# TPCC register map
Vendor: Texas Instruments
Peripheral module from a debugger description file (folder omap4430).
Registers are 32-bit, read-write, reset values left out (the file's numbers can be read two ways) unless marked. A register's access mark holds for its fields unless they carry their own. Offsets are as the file gives them; lines under a group give offsets from that group; [hi:lo] are bit positions; {n}, {i} and the like mark numbered series; 'fields as' and 'values as' point back to an identical list; <NAME> marks a mode.

## TPCC (part 1 of 2)
0x00 TPCC_PID ro — Peripheral ID Register
  [31:0] REVISION — IP Revision
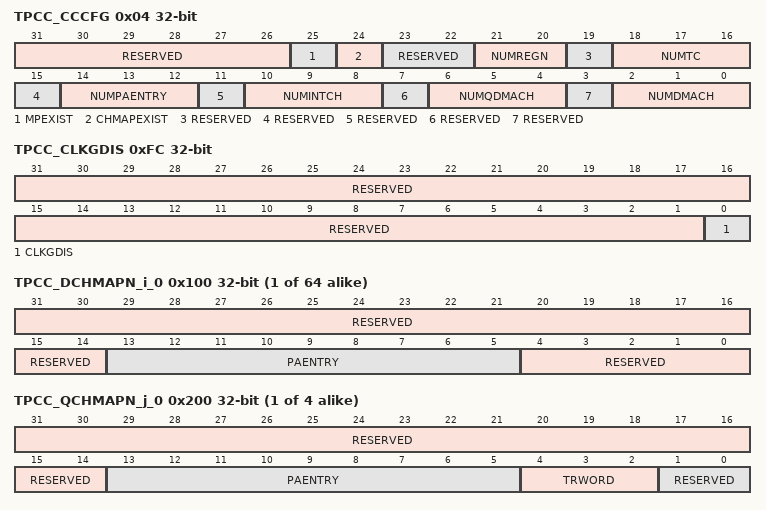
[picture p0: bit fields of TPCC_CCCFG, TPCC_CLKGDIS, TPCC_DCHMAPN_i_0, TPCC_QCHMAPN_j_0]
0x04 TPCC_CCCFG ro — CC Configuration Register
  [31:26] RESERVED — reads return 0's
  [25] MPEXIST — Memory Protection Existence0 : No memory protection.1 : Memory Protection logic included.
  [24] CHMAPEXIST — Channel Mapping Existence0 : No Channel mapping.1 : Channel mapping logic included.
  [23:22] RESERVED — reads return 0's
  [21:20] NUMREGN — Number of MP and Shadow regions
    0=NUMREGN_0_r (0 Regions); 1=NUMREGN_1_r (2 Regions); 2=NUMREGN_2_r (4 Regions); 3=NUMREGN_3_r (8 Regions)
  [19] RESERVED — reads return 0's
  [18:16] NUMTC — Number of Queues/Number of TCs
    {v}=NUMTC_{v}_r ({v+1} TC/Event Queue) (v=0..7)
  [15] RESERVED — reads return 0's
  [14:12] NUMPAENTRY — Number of PaRAM entries
    0=NUMPAENTRY_0_r (16 entries); 1=NUMPAENTRY_1_r (32 entries (unsupported setting)); 2=NUMPAENTRY_2_r (64 entries); 3=NUMPAENTRY_3_r (128 entries); 4=NUMPAENTRY_4_r (256 entries); 5=NUMPAENTRY_5_r (512 entries)
  [11] RESERVED — reads return 0's
  [10:8] NUMINTCH — Number of Interrupt Channels
    1=NUMINTCH_1_r (8 Interrupt channels); 2=NUMINTCH_2_r (16 Interrupt channels); 3=NUMINTCH_3_r (32 Interrupt channels); 4=NUMINTCH_4_r (64 Interrupt channels)
  [7] RESERVED — reads return 0's
  [6:4] NUMQDMACH — Number of QDMA Channels
    0=NUMQDMACH_0_r (No QDMA Channels); 1=NUMQDMACH_1_r (2 QDMA Channels); 2=NUMQDMACH_2_r (4 QDMA Channels); 3=NUMQDMACH_3_r (6 QDMA Channels); 4=NUMQDMACH_4_r (8 QDMA Channels)
  [3] RESERVED — reads return 0's
  [2:0] NUMDMACH — Number of DMA Channels
    0=NUMDMACH_0_r (No DMA Channels); 1=NUMDMACH_1_r (4 DMA Channels); 2=NUMDMACH_2_r (8 DMA Channels); 3=NUMDMACH_3_r (16 DMA Channels); 4=NUMDMACH_4_r (32 DMA Channels); 5=NUMDMACH_5_r (64 DMA Channels)
0xFC TPCC_CLKGDIS — Auto Clock Gate Disable
  [31:1] RESERVED — write 0's for future compatibility reads return 0's
  [0] CLKGDIS — Auto Clock Gate Disable
{0x100+4i} TPCC_DCHMAPN_i_{i} (i=0..63) — DMA Channel N Mapping Register
  [31:14] RESERVED — write 0's for future compatibility reads return 0's
  [13:5] PAENTRY — PaRAM Entry number for DMA Channel N.
  [4:0] RESERVED — write 0's for future compatibility reads return 0's
{0x200+4i} TPCC_QCHMAPN_j_{i} (i=0..3) — QDMA Channel N Mapping Register
  [31:14] RESERVED — write 0's for future compatibility reads return 0's
  [13:5] PAENTRY — PaRAM Entry number for QDMA Channel N.
  [4:2] TRWORD — TRWORD points to the specific trigger word of the PaRAM Entry defined by PAENTRY. A write to the trigger word results in a QDMA Event being recognized.
  [1:0] RESERVED — write 0's for future compatibility reads return 0's
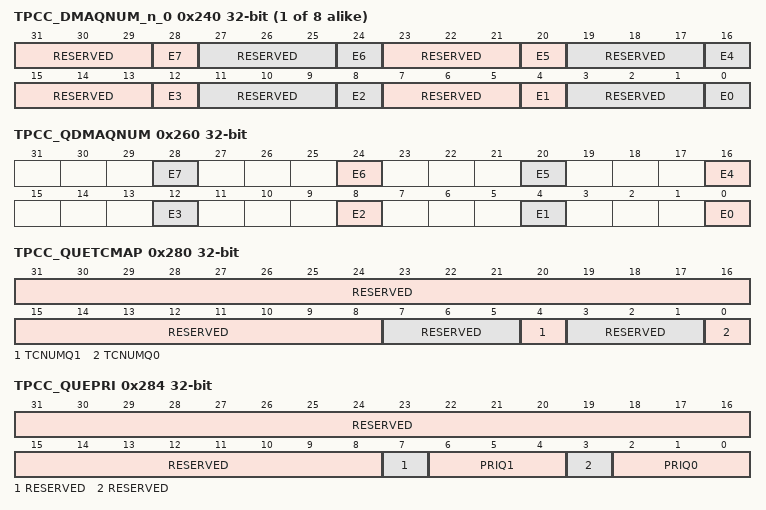
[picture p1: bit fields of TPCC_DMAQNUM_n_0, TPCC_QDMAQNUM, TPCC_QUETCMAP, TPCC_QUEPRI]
{0x240+4i} TPCC_DMAQNUM_n_{i} (i=0..7) — DMA Queue Number Register ncontains the Event queue number to be used for the corresponding DMA Channel.
  [31:29] RESERVED — Write 0s for future compatibility. Reads return 0s.
  [4n] E{n} (n=0..7) — DMA Queue Number for event #(8 * n + {n})
    0=Event En is queued on Q0; 1=Event En is queued on Q1
  [27:25] RESERVED — Write 0s for future compatibility. Reads return 0s.
  [23:21] RESERVED — Write 0s for future compatibility. Reads return 0s.
  [19:17] RESERVED — Write 0s for future compatibility. Reads return 0s.
  [15:13] RESERVED — Write 0s for future compatibility. Reads return 0s.
  [11:9] RESERVED — Write 0s for future compatibility. Reads return 0s.
  [7:5] RESERVED — Write 0s for future compatibility. Reads return 0s.
  [3:1] RESERVED — Write 0s for future compatibility. Reads return 0s.
0x260 TPCC_QDMAQNUM access per field — QDMA Queue Number RegisterContains the Event queue number to be used for the corresponding QDMA Channel.
  [all] fields
    0=Event En is queued on Q0; 1=Event En is queued on Q1
  [4n] E{n} rw (n=0..7) — QDMA Queue Number for event #{n}
0x280 TPCC_QUETCMAP — Queue to TC Mapping
  [31:8] RESERVED — Write 0s for future compatibility. Reads return 0s.
  [7:5] RESERVED — Write 0s for future compatibility. Reads return 0s.
  [4] TCNUMQ1 — TC Number for Queue N: Defines the TC number that Event Queue N TRs are written to.
    0=TRs from this queue are routed to TC0; 1=TRs from this queue are routed to TC1
  [3:1] RESERVED — Write 0s for future compatibility. Reads return 0s.
  [0] TCNUMQ0 — TC Number for Queue N: Defines the TC number that Event Queue N TRs are written to.
    values as TCNUMQ1
0x284 TPCC_QUEPRI — Queue Priority
  [31:8] RESERVED — write 0's for future compatibility reads return 0's
  [7] RESERVED — write 0's for future compatibility reads return 0's
  [6:4] PRIQ1 — Priority Level for Queue 1 Dictates the priority level used for the OPTIONS field programmation for Qn TRs. Sets the priority used for TC read and write commands.
    0=Priority 0 - Highest priority; {v}=Priority {v} (v=1..6); 7=Priority 7 - Lowest Priority
  [3] RESERVED — write 0's for future compatibility reads return 0's
  [2:0] PRIQ0 — Priority Level for Queue 0 Dictates the priority level used for the OPTIONS field programmation for Qn TRs. Sets the priority used for TC read and write commands.
    values as PRIQ1
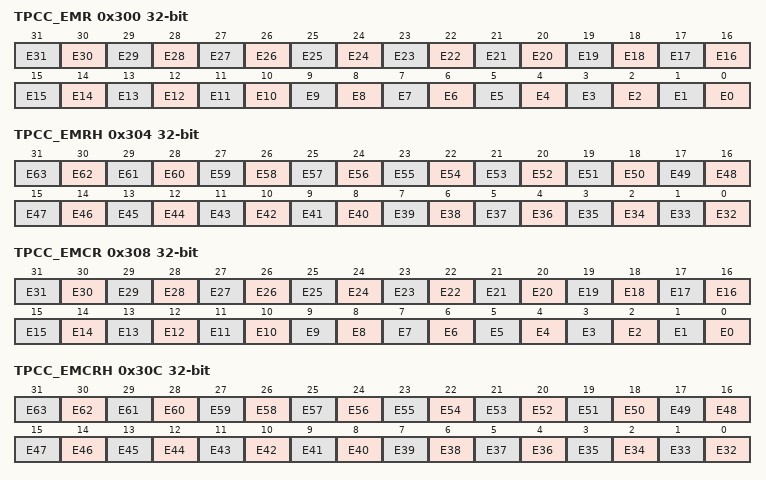
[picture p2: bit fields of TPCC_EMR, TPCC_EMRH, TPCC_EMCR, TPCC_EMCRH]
0x300 TPCC_EMR ro — Event Missed Register:The Event Missed register is set if 2 events are received without the first event being cleared or if a Null TR is serviced.Chained events (CER), Set Events (ESR), and normal events (ER) are treated individually. If any bit in the EMR register is set (and all errors (including QEMR/CCERR) were previously clear), then an error will be signaled with TPCC error interrupt.
  [n] E{n} (n=0..31) — Event Missed #{n}
0x304 TPCC_EMRH ro — Event Missed Register (High Part):The Event Missed register is set if 2 events are received without the first event being cleared or if a Null TR is serviced.Chained events (CER), Set Events (ESR), and normal events (ER) are treated individually. If any bit in the EMR register is set (and all errors (including QEMR/CCERR) were previously clear), then an error will be signaled with TPCC error interrupt.
  [n-32] E{n} (n=32..63) — Event Missed #{n}
0x308 TPCC_EMCR wo — Event Missed Clear Register:CPU write of 1 to the [n] En bit causes the [n] En bit to be cleared.CPU write of 0 has no effect.. All error bits must be cleared before additional error interrupts will be asserted by CC.
  [n] E{n} (n=0..31) — Event Missed Clear #{n}
0x30C TPCC_EMCRH wo — Event Missed Clear Register (High Part):CPU write of 1 to the [n] En bit causes the [n] En bit to be cleared.CPU write of 0 has no effect.. All error bits must be cleared before additional error interrupts will be asserted by CC.
  [n-32] E{n} (n=32..63) — Event Missed Clear #{n}
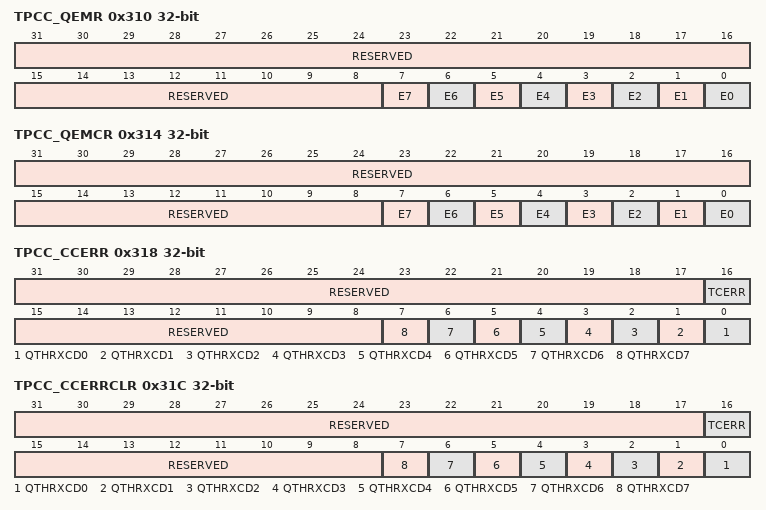
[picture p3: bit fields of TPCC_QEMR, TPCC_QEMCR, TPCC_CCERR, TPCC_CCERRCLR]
0x310 TPCC_QEMR ro — QDMA Event Missed Register:The QDMA Event Missed register is set if 2 QDMA events are detected without the first event being cleared or if a Null TR is serviced. If any bit in the register is set (and all errors (including /) were previously clear), then an error will be signaled with TPCC error interrupt.
  [31:8] RESERVED — reads return 0's
  [n] E{n} (n=0..7) — Event Missed #{n}
0x314 TPCC_QEMCR wo — QDMA Event Missed Clear Register:CPU write of 1 to the [n] En bit causes the [n] En bit to be cleared. CPU write of 0 has no effect.All error bits must be cleared before additional error interrupts will be asserted by CC.
  [31:8] RESERVED — write 0's for future compatibility
  [n] E{n} (n=0..7) — Event Missed Clear #{n}
0x318 TPCC_CCERR ro — CC Error RegisterEach bit can be cleared by writing a 1 to corresponding bit in register.If any bit in the register is set (and all errors were previously clear), then an error will be signaled with TPCC error interrupt.
  [31:17] RESERVED — reads return 0's
  [16] TCERR — Transfer Completion Code Error:0 : Total number of allowed TCCs outstanding has not been reached.1 : Total number of allowed TCCs has been reached.
  [15:8] RESERVED — reads return 0's
  [n] QTHRXCD{n} (n=0..7) — Queue Threshold Error for Q{n}:0 : Watermark/threshold has not been exceeded.1 : Watermark/threshold has been exceeded.
0x31C TPCC_CCERRCLR wo — CC Error Clear Register
  [31:17] RESERVED — write 0's for future compatibility
  [16] TCERR — Clear Error for TCERR:Write of 1 clears the value of TPCC_CCERR bit N.Writes of 0 have no affect.
  [15:8] RESERVED — write 0's for future compatibility
  [n] QTHRXCD{n} (n=0..7) — Clear error for QTHRXCD{n}:Write of 1 clears the values of QSTATN_{n}[20:16] WM, QSTATN_{n}[24] THRXCD, QTHRXCD{n}Writes of 0 have no affect.
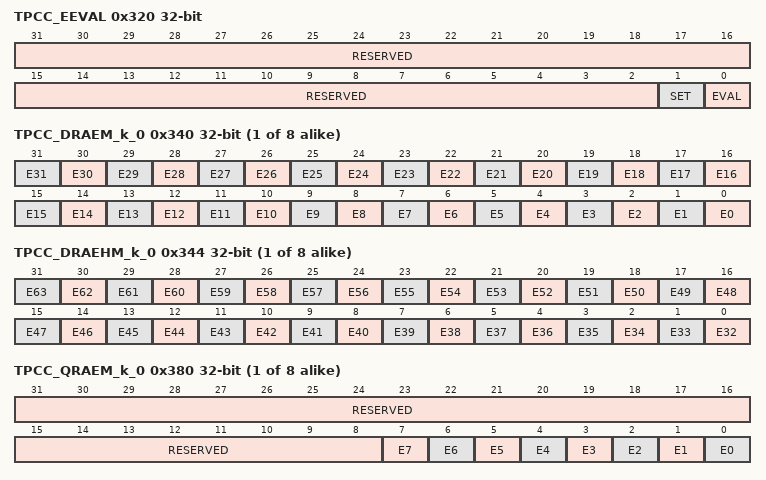
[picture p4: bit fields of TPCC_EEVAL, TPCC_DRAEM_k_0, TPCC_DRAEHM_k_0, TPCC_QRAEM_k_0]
0x320 TPCC_EEVAL wo — Error Eval Register
  [31:2] RESERVED — write 0's for future compatibility
  [1] SET — Error Interrupt Set:CPU write of 1 to the SET bit causes the TPCC error interrupt to be pulsed regardless of state of TPCC_EMR/TPCC_EMRH, TPCC_QEMR, or CPUwrite of 0 has no effect.
  [0] EVAL — Error Interrupt Evaluate:CPU write of 1 to the EVAL bit causes the TPCC error interrupt to be pulsed if any errors have not been cleared in the TPCC_EMR/TPCC_EMRH, TPCC_QEMR, or TPCC_CCERR registers.CPU write of 0 has no effect.
{0x340+8i} TPCC_DRAEM_k_{i} (i=0..7) — DMA Region Access enable for bit N in Region M:En = 0 : Accesses via Region M address space to Bit N in any DMA Channel Register are not allowed. Reads will return 0 on Bit N and writes will not modify the state of bit N. Enabled interrupt bits for bit N do not contribute to the generation of the TPCC region M interrupt.En = 1 : Accesses via Region M address space to Bit N in any DMA Channel Register are allowed. Reads will return the value from Bit N and writes will modify the state of bit N. Enabled interrupt bits for bit N do contribute to the generation of the TPCC region M interrupt.
  [n] E{n} (n=0..31) — DMA Region Access enable for Region M, bit #{n}
{0x344+8i} TPCC_DRAEHM_k_{i} (i=0..7) — DMA Region Access enable for bit N in Region M:En = 0 : Accesses via Region M address space to Bit N in any DMA Channel Register are not allowed. Reads will return 'b0 on Bit N and writes will not modify the state of bit N. Enabled interrupt bits for bit N do not contribute to the generation of the TPCC region M interrupt.En = 1 : Accesses via Region M address space to Bit N in any DMA Channel Register are allowed. Reads will return the value from Bit N and writes will modify the state of bit N. Enabled interrupt bits for bit N do contribute to the generation of the TPCC region M interrupt. En = 0 : Accesses via Region M address space to Bit N in any DMA Channel Register are not allowed. Reads will return 'b0 on Bit N and writes will not modify the state of bit N. Enabled interrupt bits for bit N do not contribute to the generation of the TPCC region M interrupt. En = 1 : Accesses via Region M address space to Bit N in any DMA Channel Register are allowed. Reads will return the value from Bit N and writes will modify the state of bit N. Enabled interrupt bits for bit N do contribute to the generation of the TPCC region M interrupt.
  [n-32] E{n} (n=32..63) — DMA Region Access enable for Region M, bit #{n}
{0x380+4i} TPCC_QRAEM_k_{i} (i=0..7) — QDMA Region Access enable for bit N in Region M:En = 0 : Accesses via Region M address space to Bit N in any QDMA Channel Register are not allowed. Reads will return 'b0 on Bit N and writes will not modify the state of bit N. Enabled interrupt bits for bit N do not contribute to the generation of the TPCC region M interrupt.En = 1 : Accesses via Region M address space to Bit N in any QDMA Channel Register are allowed. Reads will return the value from Bit N and writes will modify the state of bit N. Enabled interrupt bits for bit N do contribute to the generation of the TPCC region M interrupt.
  [31:8] RESERVED — write 0's for future compatibility reads return 0's
  [n] E{n} (n=0..7) — QDMA Region Access enable for Region M, bit #{n}
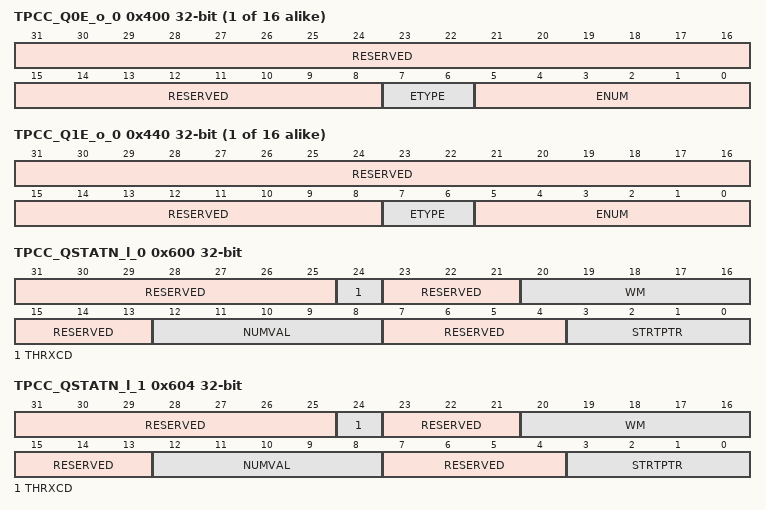
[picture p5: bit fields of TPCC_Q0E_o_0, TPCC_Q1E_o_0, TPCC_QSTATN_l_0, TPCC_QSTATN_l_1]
{0x400+4i} TPCC_Q0E_o_{i} ro (i=0..15) — Event Queue Entry Diagram for Queue 0 - Entry o
  [31:8] RESERVED — reads return 0's
  [7:6] ETYPE — Event Type:Specifies the specific Event Type for the given entry in the Event Queue.
    0=ETYPE_0_r (Event Triggered via ER); 1=ETYPE_1_r (Manual Triggered via ESR); 2=ETYPE_2_r (Chain Triggered via CER); 3=ETYPE_3_r (Auto-Triggered via QER)
  [5:0] ENUM — Event Number:Specifies the specific Event Number for the given entry in the Event Queue. For DMA Channel events (ER/ESR/CER), ENUM will range between 0 and NUM_DMACH (up to 63). For QDMA Channel events (QER), ENUM will range between 0 and NUM_QDMACH (up to 7).
{0x440+4i} TPCC_Q1E_o_{i} ro (i=0..15) — Event Queue Entry Diagram for Queue 1 - Entry o
  fields as TPCC_Q0E_o_0
0x600 TPCC_QSTATN_l_0 ro — QSTATn Register Set
  [31:25] RESERVED — reads return 0's
  [24] THRXCD — Threshold Exceeded:0 : Threshold specified by QWMTHR(A|B).Qn has not been exceeded.1 : Threshold specified by QWMTHR(A|B).Qn has been exceeded.THRXCD is cleared via WMCLRn bit.
  [23:21] RESERVED — reads return 0's
  [20:16] WM — Watermark for Maximum Queue Usage:Watermark tracks the most entries that have been in QueueN since reset or since the last time that the watermark (WM) was cleared.WM is cleared via WMCLRn bit.Legal values = 0x0 (empty) to 0x10 (full)
  [15:13] RESERVED — reads return 0's
  [12:8] NUMVAL — Number of Valid Entries in QueueN:Represents the total number of entries residing in the Queue Manager FIFO at a given instant. Always enabled.Legal values = 0x0 (empty) to 0x10 (full)
  [7:4] RESERVED — reads return 0's
  [3:0] STRTPTR — Start Pointer:Represents the offset to the head entry of QueueN, in units of *entries*. Always enabled.Legal values = 0x0 (0th entry) to 0xF (15th entry)
0x604 TPCC_QSTATN_l_1 ro — QSTATn Register Set
  fields as TPCC_QSTATN_l_0
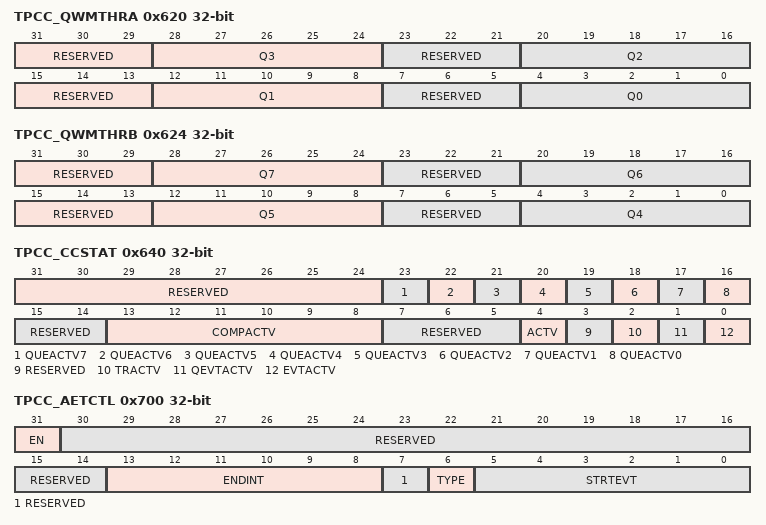
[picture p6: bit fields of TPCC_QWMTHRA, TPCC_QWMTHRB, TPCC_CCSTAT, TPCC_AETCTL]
0x620 TPCC_QWMTHRA — Queue Threshold Afor Q[3:0]: QTHRXCDn and THRXCD error bit is set when the number of Events in QueueN at an instant in time (visible via NUMVAL) equals or exceeds the value specified by QWMTHRA.Qn.Legal values = 0x0 (ever used?) to 0x10 (ever full?) A value of 0x11 disables threshold errors.
  [31:29] RESERVED — write 0's for future compatibility reads return 0's
  [8n+4:8n] Q{n} (n=0..3) — Queue Threshold for Q{n} value
  [23:21] RESERVED — write 0's for future compatibility reads return 0's
  [15:13] RESERVED — write 0's for future compatibility reads return 0's
  [7:5] RESERVED — write 0's for future compatibility reads return 0's
0x624 TPCC_QWMTHRB — Queue Threshold Bfor Q[7:4]: QTHRXCDn and THRXCD error bit is set when the number of Events in QueueN at an instant in time (visible via NUMVAL) equals or exceeds the value specified by QWMTHRB.Qn.Legal values = 0x0 (ever used?) to 0x10 (ever full?) A value of 0x11 disables threshold errors.
  [31:29] RESERVED — write 0's for future compatibility reads return 0's
  [8n-28:8n-32] Q{n} (n=4..7) — Queue Threshold for Q{n} value
  [23:21] RESERVED — write 0's for future compatibility reads return 0's
  [15:13] RESERVED — write 0's for future compatibility reads return 0's
  [7:5] RESERVED — write 0's for future compatibility reads return 0's
0x640 TPCC_CCSTAT ro — CC Status Register
  [31:24] RESERVED — reads return 0's
  [23] QUEACTV7 — Queue 7 Active0 : No Evts are queued in Q7.1 : At least one TR is queued in Q7.
  [22] QUEACTV6 — Queue 6 Active0 : No Evts are queued in Q6.1 : At least one TR is queued in Q6.
  [21] QUEACTV5 — Queue 5 Active0 : No Evts are queued in Q5.1 : At least one TR is queued in Q5.
  [20] QUEACTV4 — Queue 4 Active0 : No Evts are queued in Q4.1 : At least one TR is queued in Q4.
  [19] QUEACTV3 — Queue 3 Active0 : No Evts are queued in Q3.1 : At least one TR is queued in Q3.
  [18] QUEACTV2 — Queue 2 Active0 : No Evts are queued in Q2.1 : At least one TR is queued in Q2.
  [17] QUEACTV1 — Queue 1 Active0 : No Evts are queued in Q1.1 : At least one TR is queued in Q1.
  [16] QUEACTV0 — Queue 0 Active0 : No Evts are queued in Q0.1 : At least one TR is queued in Q0.
  [15:14] RESERVED — reads return 0's
  [13:8] COMPACTV — Completion Request Active:Counter that tracks the total number of completion requests submitted to the TC. The counter increments when a TR is submitted with TCINTEN or TCCHEN set to 1. The counter decrements for every valid completion code received from any of the external TCs. The CC will not service new TRs if COMPACTV count is already at the limit.0 : No completion requests outstanding.1: Total of 1 completion request outstanding....63 : Total of 63 completion requests are outstanding. No additional TRs will be submitted until count is less than 63.
  [7:5] RESERVED — reads return 0's
  [4] ACTV — Channel Controller Active:Channel Controller Active is a logical-OR of each of the *ACTV signals. The ACTV bit must remain high through the life of a TR.0 : Channel is idle.1 : Channel is busy.
  [3] RESERVED — reads return 0's
  [2] TRACTV — Transfer Request Active:0 : Transfer Request processing/submission logic is inactive.1 : Transfer Request processing/submission logic is active.
  [1] QEVTACTV — QDMA Event Active:0 : No enabled QDMA Events are active within the CC.1 : At least one enabled DMA Event (ER EER, ESR, CER) is active within the CC.
  [0] EVTACTV — DMA Event Active:0 : No enabled DMA Events are active within the CC.1 : At least one enabled DMA Event (ER EER, ESR, CER) is active within the CC.
0x700 TPCC_AETCTL — Advanced Event Trigger Control
  [31] EN — AET Enable:0 : AET event generation is disabled.1 : AET event generation is enabled.
  [30:14] RESERVED — write 0's for future compatibility reads return 0's
  [13:8] ENDINT — AET End Interrupt: Dictates the completion interrupt number that will force the tpcc_aet signal to be deasserted (low)
  [7] RESERVED — write 0's for future compatibility reads return 0's
  [6] TYPE — AET Event Type:0 : Event specified by STARTEVT applies to DMA Events (set by ER, ESR, or CER)1 : Event specified by STARTEVT applies to QDMA Events
  [5:0] STRTEVT — AET Start Event:Dictates the Event Number that will force the tpcc_aet signal to be asserted (high)
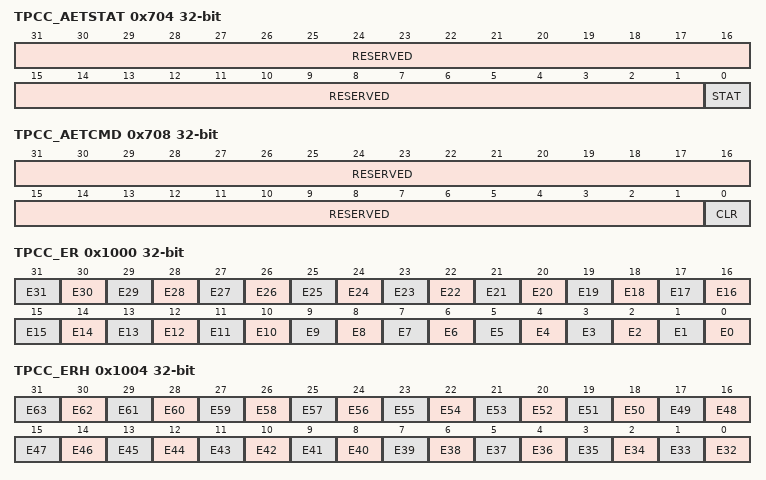
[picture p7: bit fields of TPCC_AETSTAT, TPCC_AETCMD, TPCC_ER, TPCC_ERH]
0x704 TPCC_AETSTAT ro — Advanced Event Trigger Stat
  [31:1] RESERVED — reads return 0's
  [0] STAT — AET Status:0 : tpcc_aet is currently low.1 : tpcc_aet is currently high.
0x708 TPCC_AETCMD wo — AET Command
  [31:1] RESERVED — write 0's for future compatibility
  [0] CLR — AET Clear command:CPU write of 1 to the CLR bit causes the tpcc_aet output signal and TPCC_AETSTAT register to be cleared.CPU write of 0 has no effect..
0x1000 TPCC_ER ro — Event Register:If [n] En bit is set and the [n] En bit is also set, then the corresponding DMA channel is prioritized vs. other pending DMA events for submission to the TC. [n] En bit is set when the input event #n transitions from inactive (low) to active (high), regardless of the state of [n] En bit. [n] En bit is cleared when the corresponding event is prioritized and serviced. If the [n] En bit is already set and a new inactive to active transition is detected on the input event #n input AND the corresponding bit in the register is set, then the corresponding bit in the Event Missed Register is set. Event N can be cleared via software by writing a 1 to the pseudo-register.
  [n] E{n} (n=0..31) — Event #{n}
0x1004 TPCC_ERH ro — Event Register (High Part):If [n] En bit is set and the [n] En bit is also set, then the corresponding DMA channel is prioritized vs. other pending DMA events for submission to the [n] En bit is set when the input event #n transitions from inactive (low) to active (high), regardless of the state of [n] En bit. [n] En bit is cleared when the corresponding event is prioritized and serviced. If the ERH.En bit is already set and a new inactiveTC. to active transition is detected on the input event #n input AND the corresponding bit in the register is set, then the corresponding bit in the Event Missed Register is set. Event N can be cleared via software by writing a 1 to the pseudo-register.
  [n-32] E{n} (n=32..63) — Event #{n}
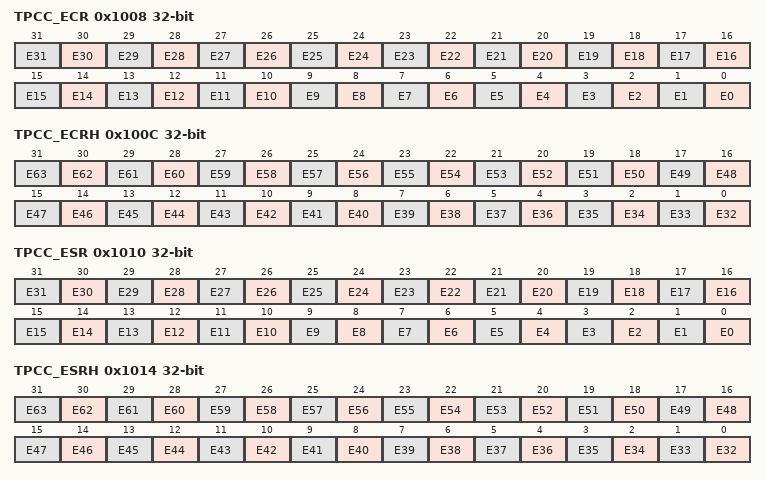
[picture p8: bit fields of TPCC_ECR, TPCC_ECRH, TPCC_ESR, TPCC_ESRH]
0x1008 TPCC_ECR wo — Event Clear Register:CPU write of 1 to the [n] En bit causes the ER.En bit to be cleared.CPU write of 0 has no effect.
  [n] E{n} (n=0..31) — Event #{n}
0x100C TPCC_ECRH wo — Event Clear Register (High Part):CPU write of 1 to the [n] En bit causes the ERH.En bit to be cleared.CPU write of 0 has no effect.
  [n-32] E{n} (n=32..63) — Event #{n}
0x1010 TPCC_ESR wo — Event Set Register:CPU write of 1 to the [n] En bit causes the [n] En bit to be set.CPU write of 0 has no effect.
  [n] E{n} (n=0..31) — Event #{n}
0x1014 TPCC_ESRH wo — Event Set Register (High Part)CPU write of 1 to the [n] En bit causes the [n] En bit to be set.CPU write of 0 has no effect.
  [n-32] E{n} (n=32..63) — Event #{n}
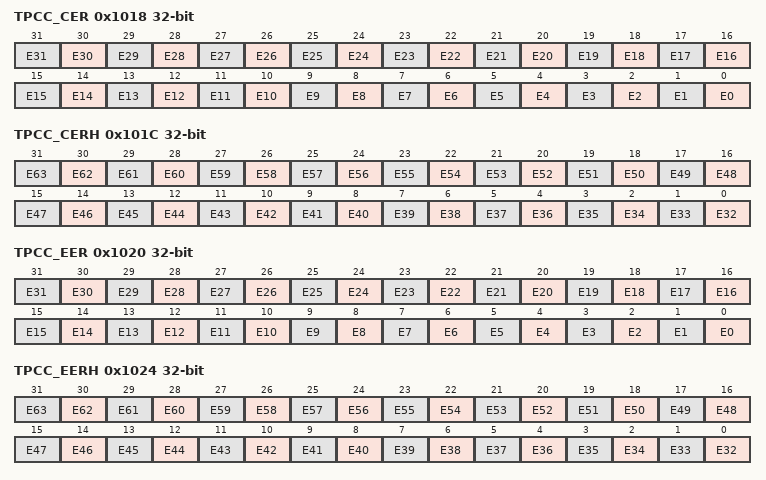
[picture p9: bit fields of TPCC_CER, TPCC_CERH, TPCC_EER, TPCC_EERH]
0x1018 TPCC_CER ro — Chained Event Register:If [n] En bit is set (regardless of state of [5] En), then the corresponding DMA channel is prioritized vs. other pending DMA events for submission to the [n] En bit is set when a chaining completion code is returned from one of the TPTCs via the completion interface, or is generated internally via Early Completion path. [n] En bit is cleared when the corresponding event is prioritized and serviced.If the [n] En bit is already set and the corresponding chaining completion code is returned from the TPCC_TC, then the corresponding bit in the Event Missed Register is set. [n] En cannot be set or cleared via software.
  [n] E{n} (n=0..31) — Event #{n}
0x101C TPCC_CERH ro — Chained Event Register (High Part):If [n] En bit is set (regardless of state of [n] En), then the corresponding DMA channel is prioritized vs. other pending DMA events for submission to the [n] En bit is set when a chaining completion code is returned from one of the TPTCs via the completion interface, or is generated internally via Early Completion path. [n] En bit is cleared when the corresponding event is prioritized and serviced. If the [n] En bit is already set and the corresponding chaining completion code is returned from the TC, then the corresponding bit in the Event Missed Register is set. [n] En cannot be set or cleared via software.
  [n-32] E{n} (n=32..63) — Event #{n}
0x1020 TPCC_EER ro — Event Enable Register:Enables DMA transfers for [n] En pending events. [n] En is set based on externally asserted events (via tpcc_eventN_pi). This register has no effect on Chained Event Register () or Event Set Register ().Note that if a bit is set in [n] En while [n] En is disabled, no action is taken.If [n] En is enabled at a later point (and [n] En has not been cleared via software) then the event will be recognized as a valid 'TR Sync' [n] En is not directly writeable.Events can be enabled via writes to and can be disabled via writes to register. [n] En = 0: [n] En is not enabled to trigger DMA transfers. [n] En = 1: [n] En is enabled to trigger DMA transfers.
  [n] E{n} (n=0..31) — Event #{n}
0x1024 TPCC_EERH ro — Event Enable Register (High Part):Enables DMA transfers for [n] En pending events. [n] En is set based on externally asserted events (via tpcc_eventN_pi).This register has no effect on Chained Event Register () or Event Set Register ().Note that if a bit is set in [n] En while [n] En is disabled, no action is taken. If [n] En is enabled at a later point (and [n] En has not been cleared via software) then the event will be recognized as a valid 'TR Sync' [n] En is not directly writeable.Events can be enabled via writes to and can be disabled via writes to register.EERH[n] En = 0: [n] En is not enabled to trigger DMA transfers. [n] En = 1: [n] En is enabled to trigger DMA transfers.
  [n-32] E{n} (n=32..63) — Event #{n}
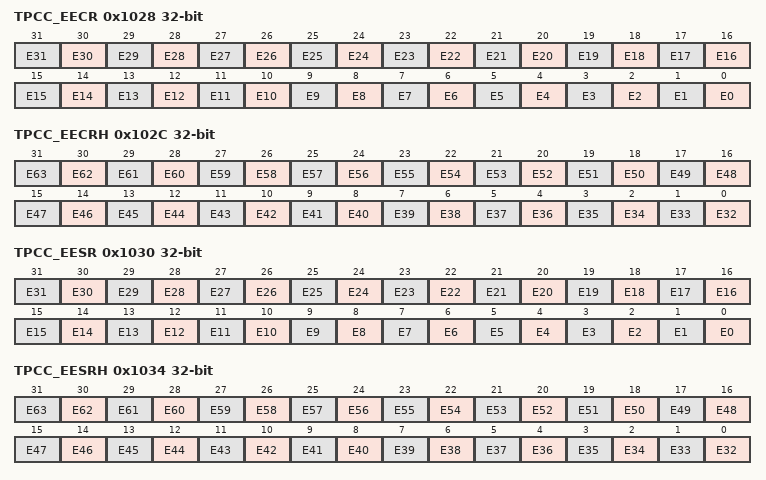
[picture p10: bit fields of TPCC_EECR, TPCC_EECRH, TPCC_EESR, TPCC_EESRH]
0x1028 TPCC_EECR wo — Event Enable Clear Register:CPU write of 1 to the [n] En bit causes the [n] En bit to be cleared.CPU write of 0 has no effect..
  [n] E{n} (n=0..31) — Event #{n}
0x102C TPCC_EECRH wo — Event Enable Clear Register (High Part):CPU write of 1 to the [n] En bit causes the [n] En bit to be cleared.CPU write of 0 has no effect..
  [n-32] E{n} (n=32..63) — Event #{n}
0x1030 TPCC_EESR wo — Event Enable Set Register:CPU write of 1 to the [n] En bit causes the [n] En bit to be set.CPU write of 0 has no effect..
  [n] E{n} (n=0..31) — Event #{n}
0x1034 TPCC_EESRH wo — Event Enable Set Register (High Part):CPU write of 1 to the [n] En bit causes the [n] En bit to be set.CPU write of 0 has no effect..
  [n-32] E{n} (n=32..63) — Event #{n}
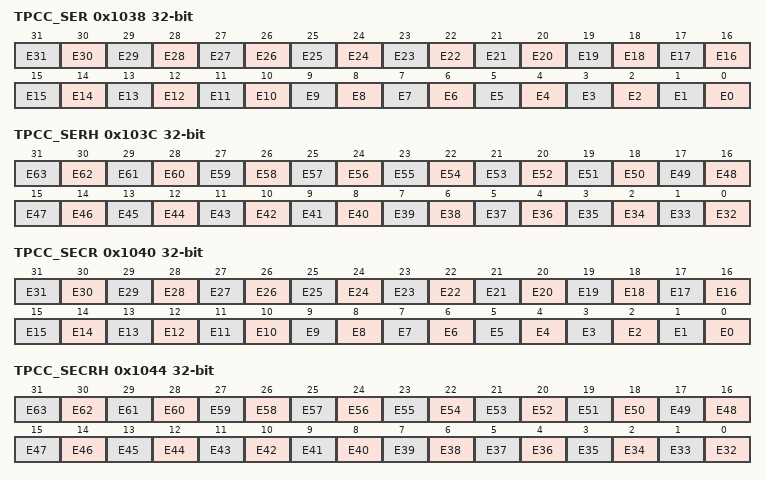
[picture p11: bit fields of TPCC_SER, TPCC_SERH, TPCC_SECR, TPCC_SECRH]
0x1038 TPCC_SER ro — Secondary Event Register:The secondary event register is used along with the Event Register () to provide information on the state of an Event.En = 0 : Event is not currently in the Event Queue.En = 1 : Event is currently stored in Event Queue.Event arbiter will not prioritize additional events.
  [n] E{n} (n=0..31) — Event #{n}
0x103C TPCC_SERH ro — Secondary Event Register (High Part):The secondary event register is used along with the Event Register () to provide information on the state of an Event.En = 0 : Event is not currently in the Event Queue.En = 1 : Event is currently stored in Event Queue.Event arbiter will not prioritize additional events.
  [n-32] E{n} (n=32..63) — Event #{n}
0x1040 TPCC_SECR wo — Secondary Event Clear Register:The secondary event clear register is used to clear the status of the SER registers.CPU write of 1 to the [n] En bit clears the register.CPU write of 0 has no effect.
  [n] E{n} (n=0..31) — Event #{n}
0x1044 TPCC_SECRH wo — Secondary Event Clear Register (High Part):The secondary event clear register is used to clear the status of the registers.CPU write of 1 to the [n] En bit clears the register.CPU write of 0 has no effect.
  [n-32] E{n} (n=32..63) — Event #{n}
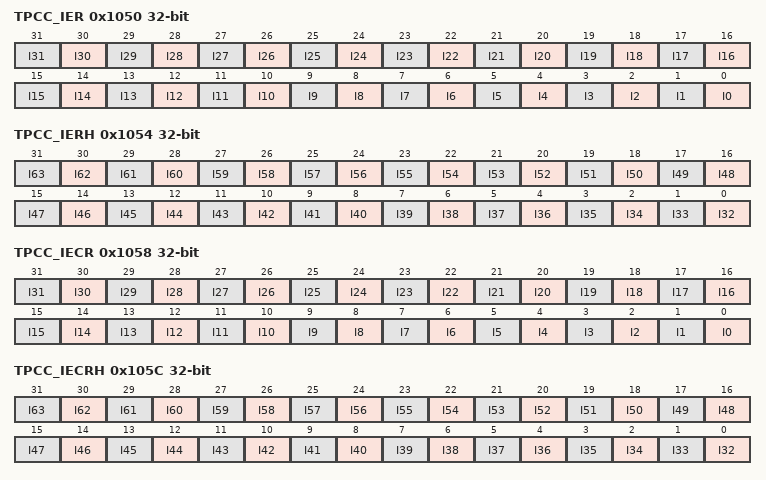
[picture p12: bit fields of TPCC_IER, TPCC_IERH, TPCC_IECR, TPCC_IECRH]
0x1050 TPCC_IER ro — Int Enable Register: [n] In is not directly writeable. Interrupts can be enabled via writes to and can be disabled via writes to register. [n] In = 0: [n] In is NOT enabled for interrupts. [n] In = 1: [n] In IS enabled for interrupts.
  [n] I{n} (n=0..31) — Interrupt associated with TCC #{n}
0x1054 TPCC_IERH ro — Int Enable Register (High Part): [n] In is not directly writeable.Interrupts can be enabled via writes to and can be disabled via writes to register. [n] In = 0: [n] In is NOT enabled for interrupts. [n] In = 1: [n] In IS enabled for interrupts.
  [n-32] I{n} (n=32..63) — Interrupt associated with TCC #{n}
0x1058 TPCC_IECR wo — Int Enable Clear Register:CPU write of 1 to the [n] In bit causes the [n] In bit to be cleared.CPU write of 0 has no effect..
  [n] I{n} (n=0..31) — Interrupt associated with TCC #{n}
0x105C TPCC_IECRH wo — Int Enable Clear Register (High Part):CPU write of 1 to the [n] In bit causes the [n] In bit to be cleared.CPU write of 0 has no effect..
  [n-32] I{n} (n=32..63) — Interrupt associated with TCC #{n}
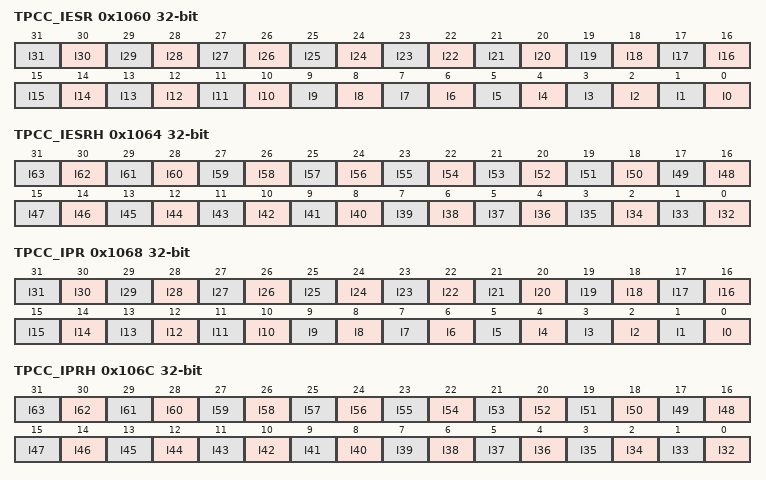
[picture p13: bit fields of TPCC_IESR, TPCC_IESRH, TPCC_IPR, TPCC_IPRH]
0x1060 TPCC_IESR wo — Int Enable Set Register:CPU write of 1 to the [n] In bit causes the [n] In bit to be set.CPU write of 0 has no effect..
  [n] I{n} (n=0..31) — Interrupt associated with TCC #{n}
0x1064 TPCC_IESRH wo — Int Enable Set Register (High Part):CPU write of 1 to the [n] In bit causes the [n] In bit to be set.CPU write of 0 has no effect..
  [n-32] I{n} (n=32..63) — Interrupt associated with TCC #{n}
0x1068 TPCC_IPR ro — Interrupt Pending Register: [n] In bit is set when a interrupt completion code with TCC of N is detected. [n] In bit is cleared via software by writing a 1 to [n] In bit.
  [n] I{n} (n=0..31) — Interrupt associated with TCC #{n}
0x106C TPCC_IPRH ro — Interrupt Pending Register (High Part): [n] In bit is set when a interrupt completion code with TCC of N is detected. [n] In bit is cleared via software by writing a 1 to [n] In bit.
  [n-32] I{n} (n=32..63) — Interrupt associated with TCC #{n}
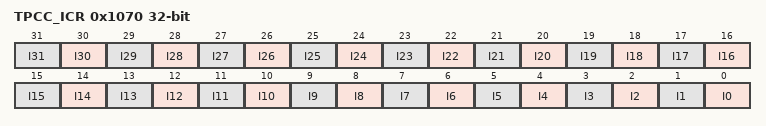
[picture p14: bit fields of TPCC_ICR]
0x1070 TPCC_ICR wo — Interrupt Clear Register:CPU write of 1 to the [n] In bit causes the [n] In bit to be cleared.CPU write of 0 has no effect.All [n] In bits must be cleared before additional interrupts will be asserted by CC.
  [n] I{n} (n=0..31) — Interrupt associated with TCC #{n}
